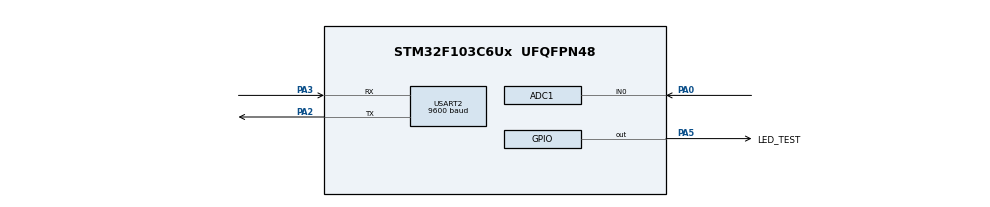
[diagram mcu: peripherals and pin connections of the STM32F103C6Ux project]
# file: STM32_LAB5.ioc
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ADC1.Channel-0\#ChannelRegularConversion=ADC_CHANNEL_0
ADC1.ContinuousConvMode=ENABLE
ADC1.NbrOfConversionFlag=1
ADC1.Rank-0\#ChannelRegularConversion=1
ADC1.SamplingTime-0\#ChannelRegularConversion=ADC_SAMPLETIME_1CYCLE_5
ADC1.master=1
Mcu.Family=STM32F1
Mcu.Name=STM32F103C6Ux
Mcu.Package=UFQFPN48
NVIC.PriorityGroup=NVIC_PRIORITYGROUP_4
NVIC.USART2_IRQn=true\:0\:0\:false\:false\:true\:true\:true
PA0-WKUP.Signal=ADCx_IN0
PA2.Mode=Asynchronous
PA2.Signal=USART2_TX
PA3.Mode=Asynchronous
PA3.Signal=USART2_RX
PA5.GPIO_Label=LED_TEST
PA5.Signal=GPIO_Output
ProjectManager.HeapSize=0x200
ProjectManager.StackSize=0x400
ProjectManager.TargetToolchain=STM32CubeIDE
RCC.APB1Freq_Value=8000000
RCC.APB2Freq_Value=8000000
SH.ADCx_IN0.0=ADC1_IN0,IN0
USART2.BaudRate=9600
USART2.VirtualMode=VM_ASYNC
VP_SYS_VS_ND.Mode=No_Debug
board=custom

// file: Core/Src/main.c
#include "main.h"

/* USER CODE BEGIN Includes */
#include <stdio.h>
#include "cmd_parser.h"
#include "uart_comm.h"
/* USER CODE END Includes */

ADC_HandleTypeDef hadc1;
UART_HandleTypeDef huart2;

/* USER CODE BEGIN PV */
uint8_t temp_rx;
//#define MAX_BUFFER_SIZE 30
//uint8_t temp = 0;
//uint8_t buffer[MAX_BUFFER_SIZE];
//uint8_t index_buffer = 0;
//uint8_t buffer_flag = 0;
/* USER CODE END PV */

void SystemClock_Config(void);
static void MX_GPIO_Init(void);
static void MX_ADC1_Init(void);
static void MX_USART2_UART_Init(void);

int main(void)
{
  HAL_Init();
  SystemClock_Config();
  MX_GPIO_Init();
  MX_ADC1_Init();
  MX_USART2_UART_Init();

  /* USER CODE BEGIN 2 */
  HAL_UART_Receive_IT(&huart2, &temp_rx, 1);
  HAL_ADC_Start(&hadc1);                    // Chạy ADC chế độ continuous
  uint8_t wake = 0x00;
  HAL_UART_Transmit(&huart2, &wake, 1, 10);
  /* USER CODE END 2 */

  while (1)
  {

      // FSM gửi !ADC=xxxx#, chờ !OK#, resend 3s
      uart_communiation_fsm();

      // Nháy LED theo chu kỳ 1s
      HAL_GPIO_TogglePin(LED_TEST_GPIO_Port, LED_TEST_Pin);
      HAL_Delay(1000);
  }
}

/* USER CODE BEGIN 4 */
void HAL_UART_RxCpltCallback(UART_HandleTypeDef *huart)
{
    if(huart->Instance == USART2)
    {
        command_parser_fsm(temp_rx);
        HAL_UART_Receive_IT(&huart2, &temp_rx, 1);
    }
}
/* USER CODE END 4 */

void SystemClock_Config(void)
{
    RCC_OscInitTypeDef RCC_OscInitStruct = {0};
    RCC_ClkInitTypeDef RCC_ClkInitStruct = {0};
    RCC_PeriphCLKInitTypeDef PeriphClkInit = {0};

    RCC_OscInitStruct.OscillatorType = RCC_OSCILLATORTYPE_HSI;
    RCC_OscInitStruct.HSIState = RCC_HSI_ON;
    RCC_OscInitStruct.HSICalibrationValue = RCC_HSICALIBRATION_DEFAULT;
    RCC_OscInitStruct.PLL.PLLState = RCC_PLL_NONE;
    HAL_RCC_OscConfig(&RCC_OscInitStruct);

    RCC_ClkInitStruct.ClockType = RCC_CLOCKTYPE_HCLK|RCC_CLOCKTYPE_SYSCLK
                                | RCC_CLOCKTYPE_PCLK1|RCC_CLOCKTYPE_PCLK2;
    RCC_ClkInitStruct.SYSCLKSource = RCC_SYSCLKSOURCE_HSI;
    RCC_ClkInitStruct.AHBCLKDivider = RCC_SYSCLK_DIV1;
    RCC_ClkInitStruct.APB1CLKDivider = RCC_HCLK_DIV1;
    RCC_ClkInitStruct.APB2CLKDivider = RCC_HCLK_DIV1;
    HAL_RCC_ClockConfig(&RCC_ClkInitStruct, FLASH_LATENCY_0);

    PeriphClkInit.PeriphClockSelection = RCC_PERIPHCLK_ADC;
    PeriphClkInit.AdcClockSelection = RCC_ADCPCLK2_DIV2;
    HAL_RCCEx_PeriphCLKConfig(&PeriphClkInit);
}

static void MX_ADC1_Init(void)
{
  ADC_ChannelConfTypeDef sConfig = {0};

  hadc1.Instance = ADC1;
  hadc1.Init.ScanConvMode = ADC_SCAN_DISABLE;
  hadc1.Init.ContinuousConvMode = ENABLE;          // Continuous Mode
  hadc1.Init.DiscontinuousConvMode = DISABLE;
  hadc1.Init.ExternalTrigConv = ADC_SOFTWARE_START;
  hadc1.Init.DataAlign = ADC_DATAALIGN_RIGHT;
  hadc1.Init.NbrOfConversion = 1;
  HAL_ADC_Init(&hadc1);

  sConfig.Channel = ADC_CHANNEL_0;                  // PA0
  sConfig.Rank = ADC_REGULAR_RANK_1;
  sConfig.SamplingTime = ADC_SAMPLETIME_1CYCLE_5;
  HAL_ADC_ConfigChannel(&hadc1, &sConfig);
}

static void MX_USART2_UART_Init(void)
{
  huart2.Instance = USART2;
  huart2.Init.BaudRate = 9600;
  huart2.Init.WordLength = UART_WORDLENGTH_8B;
  huart2.Init.StopBits = UART_STOPBITS_1;
  huart2.Init.Parity = UART_PARITY_NONE;
  huart2.Init.Mode = UART_MODE_TX_RX;
  huart2.Init.HwFlowCtl = UART_HWCONTROL_NONE;
  huart2.Init.OverSampling = UART_OVERSAMPLING_16;
  HAL_UART_Init(&huart2);
}

static void MX_GPIO_Init(void)
{
  GPIO_InitTypeDef GPIO_InitStruct = {0};

  __HAL_RCC_GPIOA_CLK_ENABLE();

  HAL_GPIO_WritePin(LED_TEST_GPIO_Port, LED_TEST_Pin, GPIO_PIN_RESET);

  GPIO_InitStruct.Pin = LED_TEST_Pin;
  GPIO_InitStruct.Mode = GPIO_MODE_OUTPUT_PP;
  GPIO_InitStruct.Pull = GPIO_NOPULL;
  GPIO_InitStruct.Speed = GPIO_SPEED_FREQ_LOW;
  HAL_GPIO_Init(LED_TEST_GPIO_Port, &GPIO_InitStruct);
}
